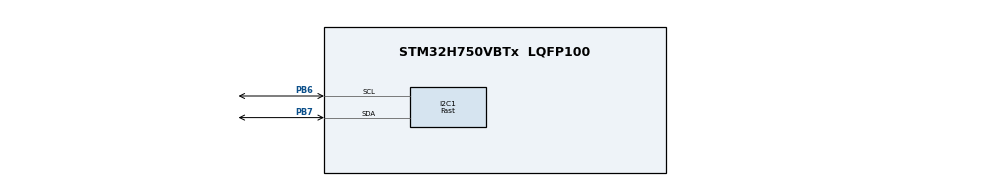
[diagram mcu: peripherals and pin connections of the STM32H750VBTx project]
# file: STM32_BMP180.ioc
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I2C1.I2C_Speed_Mode=I2C_Fast
I2C1.Timing=0x00401959
Mcu.Family=STM32H7
Mcu.Name=STM32H750VBTx
Mcu.Package=LQFP100
NVIC.PriorityGroup=NVIC_PRIORITYGROUP_4
PB6.GPIO_Pu=GPIO_PULLUP
PB6.Mode=I2C
PB6.Signal=I2C1_SCL
PB7.GPIO_Pu=GPIO_PULLUP
PB7.Mode=I2C
PB7.Signal=I2C1_SDA
ProjectManager.HeapSize=0x200
ProjectManager.StackSize=0x400
ProjectManager.TargetToolchain=STM32CubeIDE
RCC.ADCFreq_Value=129000000
RCC.APB1Freq_Value=50000000
RCC.APB2Freq_Value=100000000
RCC.APB3Freq_Value=100000000
RCC.APB4Freq_Value=100000000
RCC.CortexFreq_Value=200000000
RCC.D2PPRE1=RCC_APB1_DIV2
RCC.DIVM1=4
RCC.DIVN1=25
RCC.HCLKFreq_Value=100000000
RCC.HPRE=RCC_HCLK_DIV2
RCC.PLL2FRACN=0
RCC.PLL3FRACN=0
RCC.PLLFRACN=0
RCC.SYSCLKFreq_VALUE=200000000
RCC.SYSCLKSource=RCC_SYSCLKSOURCE_PLLCLK
RCC.USBFreq_Value=200000000
board=custom

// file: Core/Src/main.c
/* USER CODE BEGIN Header */
/**
  ******************************************************************************
  * @file           : main.c
  * @brief          : Main program body
  ******************************************************************************
  * @attention
  *
  * <h2><center>&copy; Copyright (c) 2021 STMicroelectronics.
  * All rights reserved.</center></h2>
  *
  * This software component is licensed by ST under BSD 3-Clause license,
  * the "License"; You may not use this file except in compliance with the
  * License. You may obtain a copy of the License at:
  *                        opensource.org/licenses/BSD-3-Clause
  *
  ******************************************************************************
  */
/* USER CODE END Header */
#include "main.h"

/* USER CODE BEGIN Includes */
#include <stdio.h>
#include "bmp180.h"
/* USER CODE END Includes */

/* USER CODE BEGIN PTD */
BMP180_drv_t bmp180;
/* USER CODE END PTD */

I2C_HandleTypeDef hi2c1;

void SystemClock_Config(void);
static void MX_GPIO_Init(void);
static void MX_I2C1_Init(void);

/* USER CODE BEGIN 0 */
int __io_putchar(int ch)
{
	ITM_SendChar(ch);
	return ch;
}
/* USER CODE END 0 */

int main(void)
{

  /* MCU Configuration--------------------------------------------------------*/

  /* Reset of all peripherals, Initializes the Flash interface and the Systick. */
  HAL_Init();

  /* Configure the system clock */
  SystemClock_Config();

  /* Initialize all configured peripherals */
  MX_GPIO_Init();
  MX_I2C1_Init();
  /* USER CODE BEGIN 2 */
  bmp180.oss = 0;
  BMP180_Init(&bmp180);
  /* USER CODE END 2 */

  /* Infinite loop */
  while (1)
  {

    /* USER CODE BEGIN 3 */
	  BMP180_GetEnviroment(&bmp180);
	  BMP180_Delay(1000);
  }
  /* USER CODE END 3 */
}

void SystemClock_Config(void)
{
  RCC_OscInitTypeDef RCC_OscInitStruct = {0};
  RCC_ClkInitTypeDef RCC_ClkInitStruct = {0};

  /** Supply configuration update enable
  */
  HAL_PWREx_ConfigSupply(PWR_LDO_SUPPLY);
  /** Configure the main internal regulator output voltage
  */
  __HAL_PWR_VOLTAGESCALING_CONFIG(PWR_REGULATOR_VOLTAGE_SCALE3);

  while(!__HAL_PWR_GET_FLAG(PWR_FLAG_VOSRDY)) {}
  /** Initializes the RCC Oscillators according to the specified parameters
  * in the RCC_OscInitTypeDef structure.
  */
  RCC_OscInitStruct.OscillatorType = RCC_OSCILLATORTYPE_HSI;
  RCC_OscInitStruct.HSIState = RCC_HSI_DIV1;
  RCC_OscInitStruct.HSICalibrationValue = RCC_HSICALIBRATION_DEFAULT;
  RCC_OscInitStruct.PLL.PLLState = RCC_PLL_ON;
  RCC_OscInitStruct.PLL.PLLSource = RCC_PLLSOURCE_HSI;
  RCC_OscInitStruct.PLL.PLLM = 4;
  RCC_OscInitStruct.PLL.PLLN = 25;
  RCC_OscInitStruct.PLL.PLLP = 2;
  RCC_OscInitStruct.PLL.PLLQ = 2;
  RCC_OscInitStruct.PLL.PLLR = 2;
  RCC_OscInitStruct.PLL.PLLRGE = RCC_PLL1VCIRANGE_3;
  RCC_OscInitStruct.PLL.PLLVCOSEL = RCC_PLL1VCOWIDE;
  RCC_OscInitStruct.PLL.PLLFRACN = 0;
  if (HAL_RCC_OscConfig(&RCC_OscInitStruct) != HAL_OK)
  {
    Error_Handler();
  }
  /** Initializes the CPU, AHB and APB buses clocks
  */
  RCC_ClkInitStruct.ClockType = RCC_CLOCKTYPE_HCLK|RCC_CLOCKTYPE_SYSCLK
                              |RCC_CLOCKTYPE_PCLK1|RCC_CLOCKTYPE_PCLK2
                              |RCC_CLOCKTYPE_D3PCLK1|RCC_CLOCKTYPE_D1PCLK1;
  RCC_ClkInitStruct.SYSCLKSource = RCC_SYSCLKSOURCE_PLLCLK;
  RCC_ClkInitStruct.SYSCLKDivider = RCC_SYSCLK_DIV1;
  RCC_ClkInitStruct.AHBCLKDivider = RCC_HCLK_DIV2;
  RCC_ClkInitStruct.APB3CLKDivider = RCC_APB3_DIV1;
  RCC_ClkInitStruct.APB1CLKDivider = RCC_APB1_DIV2;
  RCC_ClkInitStruct.APB2CLKDivider = RCC_APB2_DIV1;
  RCC_ClkInitStruct.APB4CLKDivider = RCC_APB4_DIV1;

  if (HAL_RCC_ClockConfig(&RCC_ClkInitStruct, FLASH_LATENCY_2) != HAL_OK)
  {
    Error_Handler();
  }
}

static void MX_I2C1_Init(void)
{

  hi2c1.Instance = I2C1;
  hi2c1.Init.Timing = 0x00401959;
  hi2c1.Init.OwnAddress1 = 0;
  hi2c1.Init.AddressingMode = I2C_ADDRESSINGMODE_7BIT;
  hi2c1.Init.DualAddressMode = I2C_DUALADDRESS_DISABLE;
  hi2c1.Init.OwnAddress2 = 0;
  hi2c1.Init.OwnAddress2Masks = I2C_OA2_NOMASK;
  hi2c1.Init.GeneralCallMode = I2C_GENERALCALL_DISABLE;
  hi2c1.Init.NoStretchMode = I2C_NOSTRETCH_DISABLE;
  if (HAL_I2C_Init(&hi2c1) != HAL_OK)
  {
    Error_Handler();
  }
  /** Configure Analogue filter
  */
  if (HAL_I2CEx_ConfigAnalogFilter(&hi2c1, I2C_ANALOGFILTER_ENABLE) != HAL_OK)
  {
    Error_Handler();
  }
  /** Configure Digital filter
  */
  if (HAL_I2CEx_ConfigDigitalFilter(&hi2c1, 0) != HAL_OK)
  {
    Error_Handler();
  }

}

static void MX_GPIO_Init(void)
{

  /* GPIO Ports Clock Enable */
  __HAL_RCC_GPIOB_CLK_ENABLE();

}

void Error_Handler(void)
{
  __disable_irq();
  while (1)
  {
  }
}

/************************ (C) COPYRIGHT STMicroelectronics *****END OF FILE****/
